# SERDES_10G0 register map
Vendor: Texas Instruments
Registers are 32-bit, read-write, reset 0x0 unless marked. A register's access mark holds for its fields unless they carry their own. Offsets are as the file gives them; [hi:lo] are bit positions; {n}, {i} and the like mark numbered series.

## SERDES_10G0 (part 4 of 5)
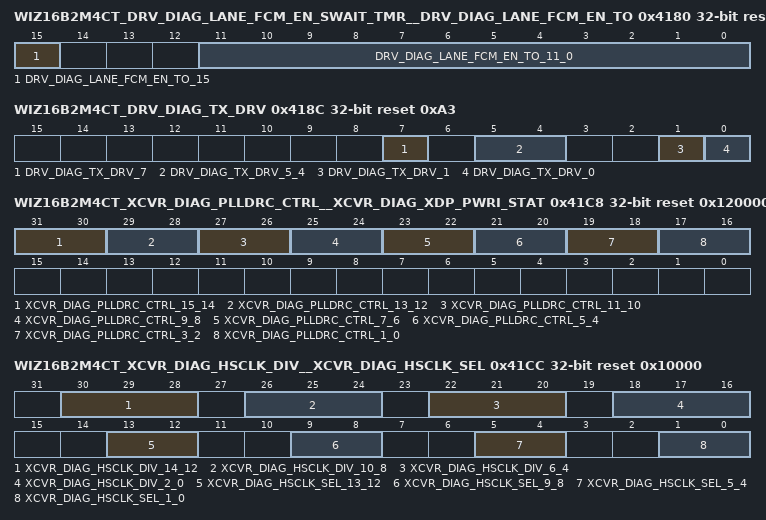
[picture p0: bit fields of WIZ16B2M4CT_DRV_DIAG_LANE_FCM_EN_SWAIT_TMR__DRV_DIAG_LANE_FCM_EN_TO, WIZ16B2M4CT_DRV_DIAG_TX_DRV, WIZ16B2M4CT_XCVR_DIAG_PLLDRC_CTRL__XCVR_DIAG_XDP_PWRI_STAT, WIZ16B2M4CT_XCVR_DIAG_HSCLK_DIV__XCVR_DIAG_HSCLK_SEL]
0x4180 WIZ16B2M4CT_DRV_DIAG_LANE_FCM_EN_SWAIT_TMR__DRV_DIAG_LANE_FCM_EN_TO reset 0x1F4 — Lane fast common mode enable timeout register
  [15] DRV_DIAG_LANE_FCM_EN_TO_15 — Bypass fast establishment of common mode enable: When enabled, the fast establishment of common mode function will be bypassed. When bypassed, the lane fast common mode enable timeout value field in this register can be used to implement a programmable delay between when fast establishment of common mode is normally initiated, and when it will complete.
  [11:0] DRV_DIAG_LANE_FCM_EN_TO_11_0 — Lane fast common mode enable timeout value: The usage of the value of this field is a function of the state of the bypass fast establishment of common mode enable bit in this register. Bypass disabled (normal operation): This specifies the maximum number of reference clock cycles the fast establishment of common mode process will wait for the tx_{p,m} signals to be reported as above the reference voltage, before timing out. The default value of this register corresponds to a delay of 20 uSec. Bypass enabled: This can be used to specify the number of reference clock cycles between when fast establishment of common mode would normally be initiated, and when it is acknowledged to have been completed.
0x4184 WIZ16B2M4CT_DRV_DIAG_LANE_FCM_EN_TUNE__DRV_DIAG_LANE_FCM_EN_MGN_TMR reset 0x96 — Lane fast common mode enable margin timer register
  [11:0] DRV_DIAG_LANE_FCM_EN_MGN_TMR_11_0 — Lane fast common mode enable margin timer value: This specifies the number of reference clock cycles the fast establishment of common mode process will enable all the margin segments for. The default value of this register corresponds to a delay of 6 uSec.
0x418C WIZ16B2M4CT_DRV_DIAG_TX_DRV reset 0xA3 — TX driver diagnostic register
  [7] DRV_DIAG_TX_DRV_7 — TX boost enable: Increases the transmitter amplitude for fast data transitions, by controlling the txda_drv_boost_en signal going to the analog.
  [5:4] DRV_DIAG_TX_DRV_5_4 — TX boost tune: Controls the transmitter boost amplitude when the transmitter boost function is enabled using the TX boost enable bit in this register, by controlling the txda_drv_boost_tune signal going to the analog. The following specifies the encoding of this field. 2'b00: Minimum Boost 2'b01: 2'b10: 2'b11: Maximum Boost
  [1] DRV_DIAG_TX_DRV_1 — TX pre-driver pull up control: When the pre-driver is disabled, this bit controls the state of the pre-driver output, by controlling the txda_drv_predrv_pullup signal going to the analog. 1'b0 : Pulled low 1'b1 : Pulled high
  [0] DRV_DIAG_TX_DRV_0 — TX driver margin type: Selects the margining type the driver will operate in, by controlling the txda_drv_margin_type signal going to the analog. 1'b0 : Classical margining - High power margining that complies with the driver differential and common-mode output impedance specs. 1'b1 : Low-Power margining - Low power margining that complies with the driver differential output impedance spec. However, this violates the driver common-mode output impedance spec to save power whenever a reduced swing driver configuration is used. Note that when fast establishment of common mode is active, the analog signal that this drives will be forced to 1'b0.
0x41C8 WIZ16B2M4CT_XCVR_DIAG_PLLDRC_CTRL__XCVR_DIAG_XDP_PWRI_STAT reset 0x120000 — Transceiver transceiver data path power island control status register
  [31:30] XCVR_DIAG_PLLDRC_CTRL_15_14 — Digital PLL clock select standard mode 3: This bit controls which full rate PLL clock is selected, when xcvr_standard_mode is set to 2'b11. 2'b00 : PLL clock 0 from the PLL 0. 2'b01 : PLL clock 1 from the PLL 0. 2'b10 : PLL clock 0 from the PLL 1. 2'b11 : PLL clock 1 from the PLL 1.
  [29:28] XCVR_DIAG_PLLDRC_CTRL_13_12 — Digital PLL data rate divider standard mode 3 value: This field will directly control the xcvr_pll_clk_datart_div signal, which controls which divided clock is selected when generating the xcvr_pll_clk_datart clock, when xcvr_standard_mode is set to 2'b11. 2'b00 : Divide by 1. 2'b01 : Divide by 2. 2'b10 : Divide by 4. 2'b11 : Divide by 8.
  [27:26] XCVR_DIAG_PLLDRC_CTRL_11_10 — Digital PLL clock select standard mode 2: This bit controls which full rate PLL clock is selected, when xcvr_standard_mode is set to 2'b10. 2'b00 : PLL clock 0 from the PLL 0. 2'b01 : PLL clock 1 from the PLL 0. 2'b10 : PLL clock 0 from the PLL 1. 2'b11 : PLL clock 1 from the PLL 1.
  [25:24] XCVR_DIAG_PLLDRC_CTRL_9_8 — Digital PLL data rate divider standard mode 2 value: This field will directly control the xcvr_pll_clk_datart_div signal, which controls which divided clock is selected when generating the xcvr_pll_clk_datart clock, when xcvr_standard_mode is set to 2'b10. 2'b00 : Divide by 1. 2'b01 : Divide by 2. 2'b10 : Divide by 4. 2'b11 : Divide by 8.
  [23:22] XCVR_DIAG_PLLDRC_CTRL_7_6 — Digital PLL clock select standard mode 1: This bit controls which full rate PLL clock is selected, when xcvr_standard_mode is set to 2'b01. 2'b00 : PLL clock 0 from the PLL 0. 2'b01 : PLL clock 1 from the PLL 0. 2'b10 : PLL clock 0 from the PLL 1. 2'b11 : PLL clock 1 from the PLL 1.
  [21:20] XCVR_DIAG_PLLDRC_CTRL_5_4 — Digital PLL data rate divider standard mode 1 value: This field will directly control the xcvr_pll_clk_datart_div signal, which controls which divided clock is selected when generating the xcvr_pll_clk_datart clock, when xcvr_standard_mode is set to 2'b01. 2'b00 : Divide by 1. 2'b01 : Divide by 2. 2'b10 : Divide by 4. 2'b11 : Divide by 8.
  [19:18] XCVR_DIAG_PLLDRC_CTRL_3_2 — Digital PLL clock select standard mode 0: This bit controls which full rate PLL clock is selected, when xcvr_standard_mode is set to 2'b00. 2'b00 : PLL clock 0 from the PLL 0. 2'b01 : PLL clock 1 from the PLL 0. 2'b10 : PLL clock 0 from the PLL 1. 2'b11 : PLL clock 1 from the PLL 1.
  [17:16] XCVR_DIAG_PLLDRC_CTRL_1_0 — Digital PLL data rate divider standard mode 0 value: This field will directly control the xcvr_pll_clk_datart_div signal, which controls which divided clock is selected when generating the xcvr_pll_clk_datart clock, when xcvr_standard_mode is set to 2'b00. 2'b00 : Divide by 1. 2'b01 : Divide by 2. 2'b10 : Divide by 4. 2'b11 : Divide by 8.
0x41CC WIZ16B2M4CT_XCVR_DIAG_HSCLK_DIV__XCVR_DIAG_HSCLK_SEL reset 0x10000 — Transceiver high speed clock select register
  [30:28] XCVR_DIAG_HSCLK_DIV_14_12 — Transceiver clock divider select standard mode 3: This field selects the divider value used to divide the selected analog high speed clock by when generating the transmit and receive clocks, when xcvr_standard_mode is set to 2'b11, by driving the xcvrda_xcvr_clk_div_sel signal to the analog, as specified below. 3'b000: Div 1 3'b001: Div 2 3'b010: Div 3 3'b011: Div 4 3'b100: Div 5 3'b101: Div 6 3'b110: Div 7 3'b111: Div 8
  [26:24] XCVR_DIAG_HSCLK_DIV_10_8 — Transceiver clock divider select standard mode 2: This field selects the divider value used to divide the selected analog high speed clock by when generating the transmit and receive clocks, when xcvr_standard_mode is set to 2'b10, by driving the xcvrda_xcvr_clk_div_sel signal to the analog, as specified below. 3'b000: Div 1 3'b001: Div 2 3'b010: Div 3 3'b011: Div 4 3'b100: Div 5 3'b101: Div 6 3'b110: Div 7 3'b111: Div 8
  [22:20] XCVR_DIAG_HSCLK_DIV_6_4 — Transceiver clock divider select standard mode 1: This field selects the divider value used to divide the selected analog high speed clock by when generating the transmit and receive clocks, when xcvr_standard_mode is set to 2'b01, by driving the xcvrda_xcvr_clk_div_sel signal to the analog, as specified below. 3'b000: Div 1 3'b001: Div 2 3'b010: Div 3 3'b011: Div 4 3'b100: Div 5 3'b101: Div 6 3'b110: Div 7 3'b111: Div 8
  [18:16] XCVR_DIAG_HSCLK_DIV_2_0 — Transceiver clock divider select standard mode 0: This field selects the divider value used to divide the selected analog high speed clock by when generating the transmit and receive clocks, when xcvr_standard_mode is set to 2'b00, by driving the xcvrda_xcvr_clk_div_sel signal to the analog, as specified below. 3'b000: Div 1 3'b001: Div 2 3'b010: Div 3 3'b011: Div 4 3'b100: Div 5 3'b101: Div 6 3'b110: Div 7 3'b111: Div 8
  [13:12] XCVR_DIAG_HSCLK_SEL_13_12 — High speed clock select standard mode 3: This specifies which analog high speed clock is selected when xcvr_standard_mode is set to 2'b11, by driving the xcvrda_clk_sel signal to the analog, as specified below. 2'b00 : clock 0. 2'b01 : clock 1. 2'b10 : Reserved. 2'b11 : Reserved.
  [9:8] XCVR_DIAG_HSCLK_SEL_9_8 — High speed clock select standard mode 2: This specifies which analog high speed clock is selected when xcvr_standard_mode is set to 2'b10, by driving the xcvrda_clk_sel signal to the analog, as specified below. 2'b00 : clock 0. 2'b01 : clock 1. 2'b10 : Reserved. 2'b11 : Reserved.
  [5:4] XCVR_DIAG_HSCLK_SEL_5_4 — High speed clock select standard mode 1: This specifies which analog high speed clock is selected when xcvr_standard_mode is set to 2'b01, by driving the xcvrda_clk_sel signal to the analog, as specified below. 2'b00 : clock 0. 2'b01 : clock 1. 2'b10 : Reserved. 2'b11 : Reserved.
  [1:0] XCVR_DIAG_HSCLK_SEL_1_0 — High speed clock select standard mode 0: This specifies which analog high speed clock is selected when xcvr_standard_mode is set to 2'b00, by driving the xcvrda_clk_sel signal to the analog, as specified below. 2'b00 : clock 0. 2'b01 : clock 1. 2'b10 : Reserved. 2'b11 : Reserved.
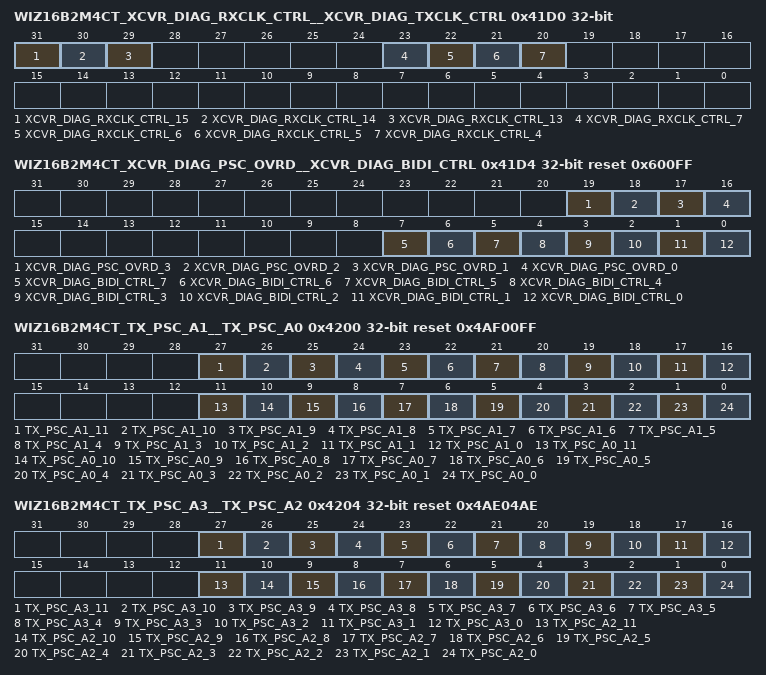
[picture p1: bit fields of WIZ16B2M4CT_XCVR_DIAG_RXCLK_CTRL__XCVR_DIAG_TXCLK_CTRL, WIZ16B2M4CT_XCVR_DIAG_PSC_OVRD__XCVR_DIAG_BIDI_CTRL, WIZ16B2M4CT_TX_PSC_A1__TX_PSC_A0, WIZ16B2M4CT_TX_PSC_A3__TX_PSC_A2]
0x41D0 WIZ16B2M4CT_XCVR_DIAG_RXCLK_CTRL__XCVR_DIAG_TXCLK_CTRL — TX clock control register
  [31] XCVR_DIAG_RXCLK_CTRL_15 — RX deserializer clock invert: This bit is used to optionally invert the deserializer clock (rxda_des_clk) for diagnostic purposes.
  [30] XCVR_DIAG_RXCLK_CTRL_14 — RX 2x clock enable: This bit enables the receiver 2x clock function, by driving the rxda_des_clk_2x_en signal going to the analog. Note that this clock is only designed to be used in modes where the data width is 20 bits. 1'b0 : Disabled 1'b1 : Enabled
  [29] XCVR_DIAG_RXCLK_CTRL_13 — RX PI E path clock select: Controls which PI clock drives the E path clocks, by driving the rxda_pi_i_drv_e_en signal going to the analog. 1'b0: E PI clock 1'b1: IQ PI clock
  [23] XCVR_DIAG_RXCLK_CTRL_7 — PI output clock divider enable standard mode 3: This bit controls the rxda_pi_out_clk_div_en to enable the PI output clock divider, when xcvr_standard_mode is set to 2'b11. 1'b0 : Disabled 1'b1 : Enabled
  [22] XCVR_DIAG_RXCLK_CTRL_6 — PI output clock divider enable standard mode 2: This bit controls the rxda_pi_out_clk_div_en to enable the PI output clock divider, when xcvr_standard_mode is set to 2'b10. 1'b0 : Disabled 1'b1 : Enabled
  [21] XCVR_DIAG_RXCLK_CTRL_5 — PI output clock divider enable standard mode 1: This bit controls the rxda_pi_out_clk_div_en to enable the PI output clock divider, when xcvr_standard_mode is set to 2'b01. 1'b0 : Disabled 1'b1 : Enabled
  [20] XCVR_DIAG_RXCLK_CTRL_4 — PI output clock divider enable standard mode 0: This bit controls the rxda_pi_out_clk_div_en to enable the PI output clock divider, when xcvr_standard_mode is set to 2'b00. 1'b0 : Disabled 1'b1 : Enabled
0x41D4 WIZ16B2M4CT_XCVR_DIAG_PSC_OVRD__XCVR_DIAG_BIDI_CTRL reset 0x600FF — Transceiver bidirectional control register
  [19] XCVR_DIAG_PSC_OVRD_3 — Receiver DFE enable mask value standard mode 3: This bit will controls the rx_dfe_eq_enable_std_mask digital signal, which can be used to mask off the rxda_dfe_eq_enable signal coming from the power state controller and going into the analog, when xcvr_standard_mode is set to 2'b11. 1'b0 : The signal will be masked off. 1'b1 : The signal to pass through unchanged.
  [18] XCVR_DIAG_PSC_OVRD_2 — Receiver DFE enable mask value standard mode 2: This bit will controls the rx_dfe_eq_enable_std_mask digital signal, which can be used to mask off the rxda_dfe_eq_enable signal coming from the power state controller and going into the analog, when xcvr_standard_mode is set to 2'b10. 1'b0 : The signal will be masked off. 1'b1 : The signal to pass through unchanged.
  [17] XCVR_DIAG_PSC_OVRD_1 — Receiver DFE enable mask value standard mode 1: This bit will controls the rx_dfe_eq_enable_std_mask digital signal, which can be used to mask off the rxda_dfe_eq_enable signal coming from the power state controller and going into the analog, when xcvr_standard_mode is set to 2'b01. 1'b0 : The signal will be masked off. 1'b1 : The signal to pass through unchanged.
  [16] XCVR_DIAG_PSC_OVRD_0 — Receiver DFE enable mask value standard mode 0: This bit will controls the rx_dfe_eq_enable_std_mask digital signal, which can be used to mask off the rxda_dfe_eq_enable signal coming from the power state controller and going into the analog, when xcvr_standard_mode is set to 2'b00. 1'b0 : The signal will be masked off. 1'b1 : The signal to pass through unchanged.
  [7] XCVR_DIAG_BIDI_CTRL_7 — Receiver enable standard mode 3: When bidirectional bumps are implemented in the transceiver, this bit is a global enable for the receiver function, when xcvr_standard_mode is set to 2'b11. When bidirectional bumps are not implemented, this bit will be reset to 1'b1, and should not be changed. When bidirectional bumps are implemented in the transceiver, this bit and the corresponding transmitter enable bit must not be set to 1'b1 at the same time. 1'b0 : RX disabled 1'b1 : RX enabled
  [6] XCVR_DIAG_BIDI_CTRL_6 — Receiver enable standard mode 2: When bidirectional bumps are implemented in the transceiver, this bit is a global enable for the receiver function, when xcvr_standard_mode is set to 2'b10. When bidirectional bumps are not implemented, this bit will be reset to 1'b1, and should not be changed. When bidirectional bumps are implemented in the transceiver, this bit and the corresponding transmitter enable bit must not be set to 1'b1 at the same time. 1'b0 : RX disabled 1'b1 : RX enabled
  [5] XCVR_DIAG_BIDI_CTRL_5 — Receiver enable standard mode 1: When bidirectional bumps are implemented in the transceiver, this bit is a global enable for the receiver function, when xcvr_standard_mode is set to 2'b01. When bidirectional bumps are not implemented, this bit will be reset to 1'b1, and should not be changed. When bidirectional bumps are implemented in the transceiver, this bit and the corresponding transmitter enable bit must not be set to 1'b1 at the same time. 1'b0 : RX disabled 1'b1 : RX enabled
  [4] XCVR_DIAG_BIDI_CTRL_4 — Receiver enable standard mode 0: When bidirectional bumps are implemented in the transceiver, this bit is a global enable for the receiver function, when xcvr_standard_mode is set to 2'b00. When bidirectional bumps are not implemented, this bit will be reset to 1'b1, and should not be changed. When bidirectional bumps are implemented in the transceiver, this bit and the corresponding transmitter enable bit must not be set to 1'b1 at the same time. 1'b0 : RX disabled 1'b1 : RX enabled
  [3] XCVR_DIAG_BIDI_CTRL_3 — Transmitter enable standard mode 3: When bidirectional bumps are implemented in the transceiver, this bit is a global enable for the transmitter function, when xcvr_standard_mode is set to 2'b11. When bidirectional bumps are not implemented, this bit will be reset to 1'b1, and should not be changed. When bidirectional bumps are implemented in the transceiver, this bit and the corresponding receiver enable bit must not be set to 1'b1 at the same time. 1'b0 : TX disabled 1'b1 : TX enabled
  [2] XCVR_DIAG_BIDI_CTRL_2 — Transmitter enable standard mode 2: When bidirectional bumps are implemented in the transceiver, this bit is a global enable for the transmitter function, when xcvr_standard_mode is set to 2'b10. When bidirectional bumps are not implemented, this bit will be reset to 1'b1, and should not be changed. When bidirectional bumps are implemented in the transceiver, this bit and the corresponding receiver enable bit must not be set to 1'b1 at the same time. 1'b0 : TX disabled 1'b1 : TX enabled
  [1] XCVR_DIAG_BIDI_CTRL_1 — Transmitter enable standard mode 1: When bidirectional bumps are implemented in the transceiver, this bit is a global enable for the transmitter function, when xcvr_standard_mode is set to 2'b01. When bidirectional bumps are not implemented, this bit will be reset to 1'b1, and should not be changed. When bidirectional bumps are implemented in the transceiver, this bit and the corresponding receiver enable bit must not be set to 1'b1 at the same time. 1'b0 : TX disabled 1'b1 : TX enabled
  [0] XCVR_DIAG_BIDI_CTRL_0 — Transmitter enable standard mode 0: When bidirectional bumps are implemented in the transceiver, this bit is a global enable for the transmitter function, when xcvr_standard_mode is set to 2'b00. When bidirectional bumps are not implemented, this bit will be reset to 1'b1, and should not be changed. When bidirectional bumps are implemented in the transceiver, this bit and the corresponding receiver enable bit must not be set to 1'b1 at the same time. 1'b0 : TX disabled 1'b1 : TX enabled
0x4200 WIZ16B2M4CT_TX_PSC_A1__TX_PSC_A0 reset 0x4AF00FF — Transmitter A0 power state definition register
  [27] TX_PSC_A1_11 — TX driver common mode enable extend control
  [26] TX_PSC_A1_10 — Force txda_lfps_sel active
  [25] TX_PSC_A1_9 — LFPS clock gate enable
  [24] TX_PSC_A1_8 — Reserved - spare
  [23] TX_PSC_A1_7 — Transmitter low current mode
  [22] TX_PSC_A1_6 — Transmitter mission mode enable
  [21] TX_PSC_A1_5 — TX driver common mode enable
  [20] TX_PSC_A1_4 — TX driver enable
  [19] TX_PSC_A1_3 — TX post-emphasis enable (C+1)
  [18] TX_PSC_A1_2 — TX pre-emphasis enable (C-1)
  [17] TX_PSC_A1_1 — TX pre-driver enable
  [16] TX_PSC_A1_0 — TX serializer enable
  [11] TX_PSC_A0_11 — TX driver common mode enable extend control: Specifies which power states the tx_cmn_mode_en_ext signal is considered valid in and can be used to force the driver to continue to be in the common mode state.
  [10] TX_PSC_A0_10 — Force txda_lfps_sel active: Setting this bit forces the txda_lfps_sel signal going to the analog to be driven active. Note that this function is implemented for additional power savings. In the analog, this signal controls a MUX select associated with the driver. Setting this bit to 1'b1 will force the MUX to select the LFPS data path. By selecting this path in low power states, instead of the serializer path, the driver inputs will be driven to 1'b0, instead of having the potential to toggle.
  [9] TX_PSC_A0_9 — LFPS clock gate enable: Enables the LFPS clock gate when an LFPS clock is required.
  [8] TX_PSC_A0_8 — Reserved - spare
  [7] TX_PSC_A0_7 — Transmitter low current mode: Enables a low current consumption mode within the common mode voltage circuit in the driver, via the txda_drv_idle_lowi_en signal going to the analog.
  [6] TX_PSC_A0_6 — Transmitter mission mode enable: Enables the analog circuits in the driver required to run in mission mode, via the txda_drv_mission_en signal going to the analog.
  [5] TX_PSC_A0_5 — TX driver common mode enable: Enables the common mode voltage circuits in the driver.
  [4] TX_PSC_A0_4 — TX driver enable: Enables the transmitter driver, via the H bridge driver controller.
  [3] TX_PSC_A0_3 — TX post-emphasis enable (C+1): Enables the transmitter circuits related to the post-emphasis function.
  [2] TX_PSC_A0_2 — TX pre-emphasis enable (C-1): Enables the transmitter circuits related to the pre-emphasis function.
  [1] TX_PSC_A0_1 — TX pre-driver enable: Enables the transmitter pre-driver, driver data selection MUX, and receiver detect.
  [0] TX_PSC_A0_0 — TX serializer enable: Enables the serializer and related clock divider circuits.
0x4204 WIZ16B2M4CT_TX_PSC_A3__TX_PSC_A2 reset 0x4AE04AE — Transmitter A2 power state definition register
  [27] TX_PSC_A3_11 — TX driver common mode enable extend control
  [26] TX_PSC_A3_10 — Force txda_lfps_sel active
  [25] TX_PSC_A3_9 — LFPS clock gate enable
  [24] TX_PSC_A3_8 — Reserved - spare
  [23] TX_PSC_A3_7 — Transmitter low current mode
  [22] TX_PSC_A3_6 — Transmitter mission mode enable
  [21] TX_PSC_A3_5 — TX driver common mode enable
  [20] TX_PSC_A3_4 — TX driver enable
  [19] TX_PSC_A3_3 — TX post-emphasis enable (C+1)
  [18] TX_PSC_A3_2 — TX pre-emphasis enable (C-1)
  [17] TX_PSC_A3_1 — TX pre-driver enable
  [16] TX_PSC_A3_0 — TX serializer enable
  [11] TX_PSC_A2_11 — TX driver common mode enable extend control
  [10] TX_PSC_A2_10 — Force txda_lfps_sel active
  [9] TX_PSC_A2_9 — LFPS clock gate enable
  [8] TX_PSC_A2_8 — Reserved - spare
  [7] TX_PSC_A2_7 — Transmitter low current mode
  [6] TX_PSC_A2_6 — Transmitter mission mode enable
  [5] TX_PSC_A2_5 — TX driver common mode enable
  [4] TX_PSC_A2_4 — TX driver enable
  [3] TX_PSC_A2_3 — TX post-emphasis enable (C+1)
  [2] TX_PSC_A2_2 — TX pre-emphasis enable (C-1)
  [1] TX_PSC_A2_1 — TX pre-driver enable
  [0] TX_PSC_A2_0 — TX serializer enable
0x4244 WIZ16B2M4CT_TX_RCVDET_ST_TMR__TX_RCVDET_EN_TMR reset 0x9C40000 — Transmit receiver detect enable timer register
  [31:16] TX_RCVDET_ST_TMR_15_0 — Start wait time value: This is the number of clocks the receiver detect state machine waits between driving the txda_rcvdet_start signal active and checking the results on the txda_rcvdet_detected_n signal coming from the analog. The default required wait time is 100us.
0x6000 WIZ16B2M4CT_RESERVEDBIT13ADDRESSB — Reserved Address bit 13 area B
  [31:0] RES_BIT13_ADR_B — Write only test region B
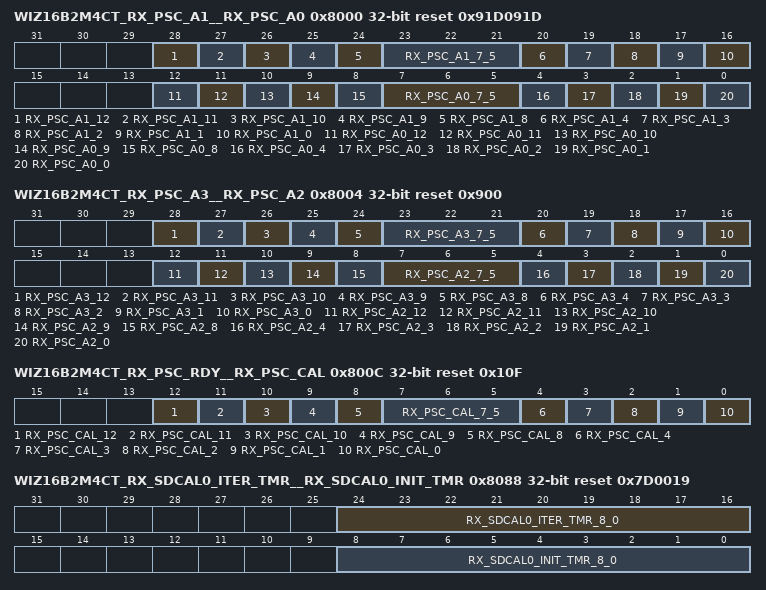
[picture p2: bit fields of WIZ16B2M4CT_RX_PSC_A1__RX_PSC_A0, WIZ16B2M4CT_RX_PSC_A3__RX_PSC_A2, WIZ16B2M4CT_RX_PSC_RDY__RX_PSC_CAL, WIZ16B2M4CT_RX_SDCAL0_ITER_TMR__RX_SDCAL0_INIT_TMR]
0x8000 WIZ16B2M4CT_RX_PSC_A1__RX_PSC_A0 reset 0x91D091D — Receiver A0 power state definition register
  [28] RX_PSC_A1_12 — RX signal detect enable extend control
  [27] RX_PSC_A1_11 — RX signal detect filter enable
  [26] RX_PSC_A1_10 — RX LFPS detect filter enable
  [25] RX_PSC_A1_9 — Reserved - spare
  [24] RX_PSC_A1_8 — RX signal detect enable
  [23:21] RX_PSC_A1_7_5 — Reserved - spare
  [20] RX_PSC_A1_4 — RX equalizer engine enable
  [19] RX_PSC_A1_3 — RX DFE equalization enable.
  [18] RX_PSC_A1_2 — RX PI enable
  [17] RX_PSC_A1_1 — RX e path enable (calibration and eye surf only)
  [16] RX_PSC_A1_0 — RX enable
  [12] RX_PSC_A0_12 — RX signal detect enable extend control: Specifies which power states the rx_sig_det_en_ext signal is considered valid in and can be used to force the signal detect functions to remain on.
  [11] RX_PSC_A0_11 — RX signal detect filter enable: Enables the receiver signal detect filter function in the digital receiver controller.
  [10] RX_PSC_A0_10 — RX LFPS detect filter enable: Enables the receiver LFPS detect filter function in the digital receiver controller.
  [9] RX_PSC_A0_9 — Reserved - spare
  [8] RX_PSC_A0_8 — RX signal detect enable: Enables the receiver signal detect function. This drives the rxda_sd_en signal going to the analog. Note that this bit needs to be active for LFPS detect functions to work, because these functions share the same analog circuits.
  [7:5] RX_PSC_A0_7_5 — Reserved - spare
  [4] RX_PSC_A0_4 — RX equalizer engine enable: Specifies which power state the REE runs in. 1'b0: Disabled 1'b1: Enabled
  [3] RX_PSC_A0_3 — RX DFE equalization enable: Enables the receiver DFE equalization circuits, via the rxda_dfe_eq_enable signal.
  [2] RX_PSC_A0_2 — RX PI enable: Enables the receiver circuits related to the PI and associated clocking components.
  [1] RX_PSC_A0_1 — RX e path enable (calibration and eye surf only) : Enables the receiver circuits related to the eye plot PI and e path deserializer for calibration and eye surf.
  [0] RX_PSC_A0_0 — RX enable: Enables the receiver circuits related to the CDRLF, Sampler, FE, and Deserializer.
0x8004 WIZ16B2M4CT_RX_PSC_A3__RX_PSC_A2 reset 0x900 — Receiver A2 power state definition register
  [28] RX_PSC_A3_12 — RX signal detect enable extend control
  [27] RX_PSC_A3_11 — RX signal detect filter enable
  [26] RX_PSC_A3_10 — RX LFPS detect filter enable
  [25] RX_PSC_A3_9 — Reserved - spare
  [24] RX_PSC_A3_8 — RX signal detect enable
  [23:21] RX_PSC_A3_7_5 — Reserved - spare
  [20] RX_PSC_A3_4 — RX equalizer engine enable
  [19] RX_PSC_A3_3 — RX DFE equalization enable.
  [18] RX_PSC_A3_2 — RX PI enable
  [17] RX_PSC_A3_1 — RX e path enable (calibration and eye surf only)
  [16] RX_PSC_A3_0 — RX enable
  [12] RX_PSC_A2_12 — RX signal detect enable extend control
  [11] RX_PSC_A2_11 — RX signal detect filter enable
  [10] RX_PSC_A2_10 — RX LFPS detect filter enable
  [9] RX_PSC_A2_9 — Reserved - spare
  [8] RX_PSC_A2_8 — RX signal detect enable
  [7:5] RX_PSC_A2_7_5 — Reserved - spare
  [4] RX_PSC_A2_4 — RX equalizer engine enable
  [3] RX_PSC_A2_3 — RX DFE equalization enable.
  [2] RX_PSC_A2_2 — RX PI enable
  [1] RX_PSC_A2_1 — RX e path enable (calibration and eye surf only)
  [0] RX_PSC_A2_0 — RX enable
0x800C WIZ16B2M4CT_RX_PSC_RDY__RX_PSC_CAL reset 0x10F — Receiver calibration power state definition register
  [12] RX_PSC_CAL_12 — RX signal detect enable extend control
  [11] RX_PSC_CAL_11 — RX signal detect filter enable
  [10] RX_PSC_CAL_10 — RX LFPS detect filter enable
  [9] RX_PSC_CAL_9 — Reserved - spare
  [8] RX_PSC_CAL_8 — RX signal detect enable
  [7:5] RX_PSC_CAL_7_5 — Reserved - spare
  [4] RX_PSC_CAL_4 — RX equalizer engine enable
  [3] RX_PSC_CAL_3 — RX DFE equalization enable.
  [2] RX_PSC_CAL_2 — RX PI enable
  [1] RX_PSC_CAL_1 — RX e path enable (calibration and eye surf only)
  [0] RX_PSC_CAL_0 — RX enable
0x8088 WIZ16B2M4CT_RX_SDCAL0_ITER_TMR__RX_SDCAL0_INIT_TMR reset 0x7D0019 — Signal detect calibration 0 initialization timer register
  [24:16] RX_SDCAL0_ITER_TMR_8_0 — Iteration wait timer value: This is the number of cmn_ref_clk clocks to wait between when a value is placed on the calibration code signals going to the analog, and when the comparator value coming from the analog circuits can be checked. Note that this results in the minimum number of cmn_ref_clk clocks required to wait 5 uSec. Note that this should never be set to a value of less than 3.
  [8:0] RX_SDCAL0_INIT_TMR_8_0 — Initialization wait timer value: This is the number of cmn_ref_clk clocks to wait between when the analog calibration circuits are enabled, and when the first values are placed on the calibration code signals going to the analog. Note that this results in the minimum number of cmn_ref_clk clocks required to wait 1 uSec. Note that this should never be set to a value of less than 1.
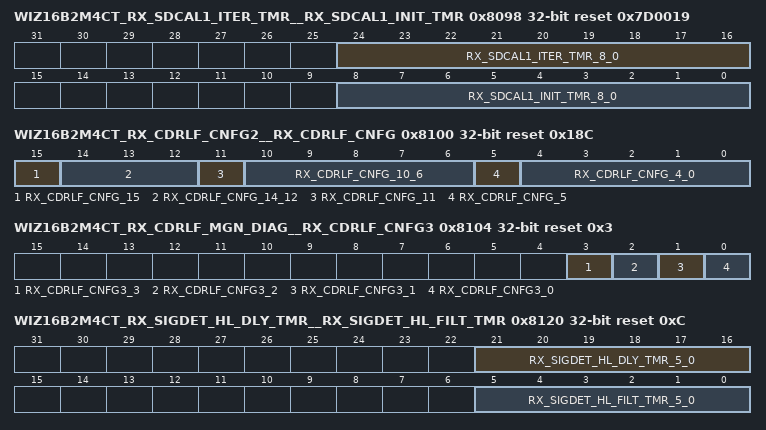
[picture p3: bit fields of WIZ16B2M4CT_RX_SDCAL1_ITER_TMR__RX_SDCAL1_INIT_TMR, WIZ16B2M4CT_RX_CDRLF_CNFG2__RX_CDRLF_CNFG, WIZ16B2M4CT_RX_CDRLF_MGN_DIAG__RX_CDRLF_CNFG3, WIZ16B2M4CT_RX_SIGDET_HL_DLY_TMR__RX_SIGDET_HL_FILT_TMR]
0x8098 WIZ16B2M4CT_RX_SDCAL1_ITER_TMR__RX_SDCAL1_INIT_TMR reset 0x7D0019 — Signal detect calibration 1 initialization timer register
  [24:16] RX_SDCAL1_ITER_TMR_8_0 — Iteration wait timer value: This is the number of cmn_ref_clk clocks to wait between when a value is placed on the calibration code signals going to the analog, and when the comparator value coming from the analog circuits can be checked. Note that this results in the minimum number of cmn_ref_clk clocks required to wait 5 uSec. Note that this should never be set to a value of less than 3.
  [8:0] RX_SDCAL1_INIT_TMR_8_0 — Initialization wait timer value: This is the number of cmn_ref_clk clocks to wait between when the analog calibration circuits are enabled, and when the first values are placed on the calibration code signals going to the analog. Note that this results in the minimum number of cmn_ref_clk clocks required to wait 1 uSec. Note that this should never be set to a value of less than 1.
0x8100 WIZ16B2M4CT_RX_CDRLF_CNFG2__RX_CDRLF_CNFG reset 0x18C — CDRLF configuration register (!)
  [15] RX_CDRLF_CNFG_15 — CDLRF reset hold: When active (1'b1), the CDRLF will be held in reset beyond the time that it would normally be released by its asynchronous release signals. The CDRLF will be held in reset until this bit is deactivated (1'b0). Note: This signal is intended be for verification purposes only. It should be set to 1'b0 for normal operation.
  [14:12] RX_CDRLF_CNFG_14_12 — CDRLF diagnostic mode control: This field controls the information driven on the rx_pi_val_ln_{15:0}[7:0] signal, when in diagnostics mode.
  [11] RX_CDRLF_CNFG_11 — CDRLF second order loop disable: Activating (1'b1) this bit will disable the CDRLF second order loop. Note: This signal is intended be for verification purposes only. It should be set to 1'b0 for normal operation.
  [10:6] RX_CDRLF_CNFG_10_6 — CDRLF second order loop sigma delta update rate: This is the value that is added to or subtracted from the second order loop accumulator register when the serial data sample clock is detected as being out of phase with the serial data on a given parallel data word cycle. This is part of the CDRLF averaging function.
  [5] RX_CDRLF_CNFG_5 — CDRLF first order loop disable: Activating (1'b1) this bit will disable the CDRLF first order loop. Note: This signal is intended to be for verification purposes only. It should be set to 1'b0 for normal operation.
  [4:0] RX_CDRLF_CNFG_4_0 — CDRLF first order loop sigma delta update rate: This is the value that is added to or subtracted from the first order loop accumulator register when the serial data sample clock is detected as being out of phase with the serial data on a given parallel data word cycle. This is part of the CDRLF averaging function.
0x8104 WIZ16B2M4CT_RX_CDRLF_MGN_DIAG__RX_CDRLF_CNFG3 reset 0x3 — CDRLF configuration register 3 (!)
  [3] RX_CDRLF_CNFG3_3 — CDRLF data filter enable standard mode 3 : Enables the filter function for the data that feeds into the CDRLF from the deserializer, using the rxda_cdrlf_data_filter_en_n signal, when xcvr_standard_mode is set to 2'b11. 1'b0 : Enable filter of 1010 patterns from the CDRLF. 1'b1 : No CDRLF data filter function enabled.
  [2] RX_CDRLF_CNFG3_2 — CDRLF data filter enable standard mode 2 : Enables the filter function for the data that feeds into the CDRLF from the deserializer, using the rxda_cdrlf_data_filter_en_n signal, when xcvr_standard_mode is set to 2'b10. 1'b0 : Enable filter of 1010 patterns from the CDRLF. 1'b1 : No CDRLF data filter function enabled.
  [1] RX_CDRLF_CNFG3_1 — CDRLF data filter enable standard mode 1 : Enables the filter function for the data that feeds into the CDRLF from the deserializer, using the rxda_cdrlf_data_filter_en_n signal, when xcvr_standard_mode is set to 2'b01. 1'b0 : Enable filter of 1010 patterns from the CDRLF. 1'b1 : No CDRLF data filter function enabled.
  [0] RX_CDRLF_CNFG3_0 — CDRLF data filter enable standard mode 0 : Enables the filter function for the data that feeds into the CDRLF from the deserializer, using the rxda_cdrlf_data_filter_en_n signal, when xcvr_standard_mode is set to 2'b00. 1'b0 : Enable filter of 1010 patterns from the CDRLF. 1'b1 : No CDRLF data filter function enabled.
0x8120 WIZ16B2M4CT_RX_SIGDET_HL_DLY_TMR__RX_SIGDET_HL_FILT_TMR reset 0xC — Receiver signal detect filter high to low filter timer register (!)
  [21:16] RX_SIGDET_HL_DLY_TMR_5_0 — Signal detect filter high to low delay timer value: This is the value loaded into the delay timer in the signal detect high to low filter circuit.
  [5:0] RX_SIGDET_HL_FILT_TMR_5_0 — Signal detect filter high to low filter timer value: This is the value loaded into the filter timer in the signal detect high to low filter circuit.
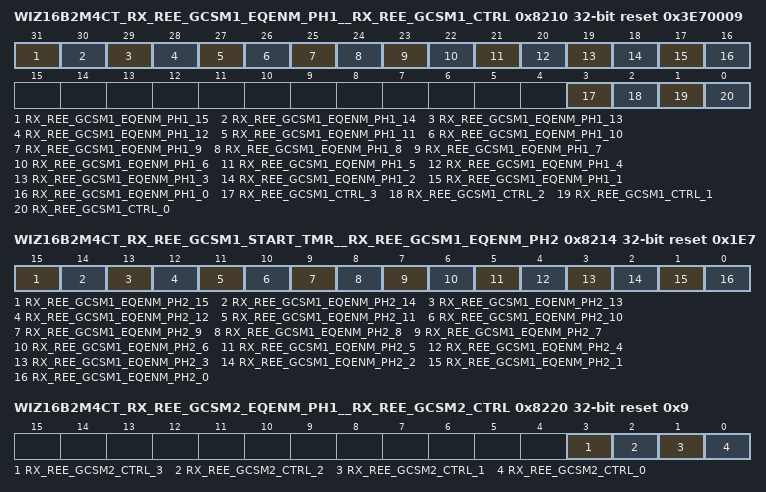
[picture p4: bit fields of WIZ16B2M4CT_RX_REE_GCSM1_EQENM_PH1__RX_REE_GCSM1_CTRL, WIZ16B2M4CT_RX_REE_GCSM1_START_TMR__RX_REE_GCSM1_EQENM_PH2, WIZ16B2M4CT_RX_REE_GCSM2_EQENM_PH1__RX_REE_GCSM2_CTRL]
0x8210 WIZ16B2M4CT_RX_REE_GCSM1_EQENM_PH1__RX_REE_GCSM1_CTRL reset 0x3E70009 — REE general control state machine 1 control register
  [31] RX_REE_GCSM1_EQENM_PH1_15 — Reserved - spare
  [30] RX_REE_GCSM1_EQENM_PH1_14 — Ignore 1010 controller : When set to 1'b1, this function is enabled when the general control state machine 1 is controlling the REE.
  [29] RX_REE_GCSM1_EQENM_PH1_13 — TX equalization evaluator : When set to 1'b1, this function is enabled when the general control state machine 1 is controlling the REE.
  [28] RX_REE_GCSM1_EQENM_PH1_12 — TX post cursor control : When set to 1'b1, this function is enabled when the general control state machine 1 is controlling the REE.
  [27] RX_REE_GCSM1_EQENM_PH1_11 — TX pre cursor control : When set to 1'b1, this function is enabled when the general control state machine 1 is controlling the REE.
  [26] RX_REE_GCSM1_EQENM_PH1_10 — Short channel correction : When set to 1'b1, this function is enabled when the general control state machine 1 is controlling the REE.
  [25] RX_REE_GCSM1_EQENM_PH1_9 — RX attenuation : When set to 1'b1, this function is enabled when the general control state machine 1 is controlling the REE.
  [24] RX_REE_GCSM1_EQENM_PH1_8 — RX VGA gain : When set to 1'b1, this function is enabled when the general control state machine 1 is controlling the REE.
  [23] RX_REE_GCSM1_EQENM_PH1_7 — RX offset correction coefficient : When set to 1'b1, this function is enabled when the general control state machine 1 is controlling the REE.
  [22] RX_REE_GCSM1_EQENM_PH1_6 — RX peaking amp gain : When set to 1'b1, this function is enabled when the general control state machine 1 is controlling the REE.
  [21] RX_REE_GCSM1_EQENM_PH1_5 — RX low frequency equalizer adaptive control : When set to 1'b1, this function is enabled when the general control state machine 1 is controlling the REE.
  [20] RX_REE_GCSM1_EQENM_PH1_4 — Reserved - spare
  [19] RX_REE_GCSM1_EQENM_PH1_3 — Reserved - spare
  [18] RX_REE_GCSM1_EQENM_PH1_2 — RX tap 3 : When set to 1'b1, this function is enabled when the general control state machine 1 is controlling the REE.
  [17] RX_REE_GCSM1_EQENM_PH1_1 — RX tap 2 : When set to 1'b1, this function is enabled when the general control state machine 1 is controlling the REE.
  [16] RX_REE_GCSM1_EQENM_PH1_0 — RX tap 1 : When set to 1'b1, this function is enabled when the general control state machine 1 is controlling the REE.
  [3] RX_REE_GCSM1_CTRL_3 — Equalization function reset enable: Enables the reset of the functions controlled by this state machine, using the rx_ree_fcn_reset_n signal, when the equalization mode changes. 1'b1 : Enabled 1'b0 : Disabled
  [2] RX_REE_GCSM1_CTRL_2 — Loop enable: Controls when the equalization functions in this state machine are run one time or loop continuously.
  [1] RX_REE_GCSM1_CTRL_1 — Force run equalization: Setting this bit to a 1'b1, will force the general control state machine to run, independent of the macro functions that normally run the equalization.
  [0] RX_REE_GCSM1_CTRL_0 — Enable: This bit enables the general control state machine function. 1'b1 : Enabled 1'b0 : Disabled
0x8214 WIZ16B2M4CT_RX_REE_GCSM1_START_TMR__RX_REE_GCSM1_EQENM_PH2 reset 0x1E7 — REE general control state machine 1 phase 2 equalization enable mask register
  [15] RX_REE_GCSM1_EQENM_PH2_15 — Reserved - spare
  [14] RX_REE_GCSM1_EQENM_PH2_14 — Ignore 1010 controller : When set to 1'b1, this function is enabled when the general control state machine 1 is controlling the REE.
  [13] RX_REE_GCSM1_EQENM_PH2_13 — TX equalization evaluator : When set to 1'b1, this function is enabled when the general control state machine 1 is controlling the REE.
  [12] RX_REE_GCSM1_EQENM_PH2_12 — TX post cursor control : When set to 1'b1, this function is enabled when the general control state machine 1 is controlling the REE.
  [11] RX_REE_GCSM1_EQENM_PH2_11 — TX pre cursor control : When set to 1'b1, this function is enabled when the general control state machine 1 is controlling the REE.
  [10] RX_REE_GCSM1_EQENM_PH2_10 — Short channel correction : When set to 1'b1, this function is enabled when the general control state machine 1 is controlling the REE.
  [9] RX_REE_GCSM1_EQENM_PH2_9 — RX attenuation : When set to 1'b1, this function is enabled when the general control state machine 1 is controlling the REE.
  [8] RX_REE_GCSM1_EQENM_PH2_8 — RX VGA gain : When set to 1'b1, this function is enabled when the general control state machine 1 is controlling the REE.
  [7] RX_REE_GCSM1_EQENM_PH2_7 — RX offset correction coefficient : When set to 1'b1, this function is enabled when the general control state machine 1 is controlling the REE.
  [6] RX_REE_GCSM1_EQENM_PH2_6 — RX peaking amp gain : When set to 1'b1, this function is enabled when the general control state machine 1 is controlling the REE.
  [5] RX_REE_GCSM1_EQENM_PH2_5 — RX low frequency equalizer adaptive control : When set to 1'b1, this function is enabled when the general control state machine 1 is controlling the REE.
  [4] RX_REE_GCSM1_EQENM_PH2_4 — Reserved - spare
  [3] RX_REE_GCSM1_EQENM_PH2_3 — Reserved - spare
  [2] RX_REE_GCSM1_EQENM_PH2_2 — RX tap 3 : When set to 1'b1, this function is enabled when the general control state machine 1 is controlling the REE.
  [1] RX_REE_GCSM1_EQENM_PH2_1 — RX tap 2 : When set to 1'b1, this function is enabled when the general control state machine 1 is controlling the REE.
  [0] RX_REE_GCSM1_EQENM_PH2_0 — RX tap 1 : When set to 1'b1, this function is enabled when the general control state machine 1 is controlling the REE.
0x8220 WIZ16B2M4CT_RX_REE_GCSM2_EQENM_PH1__RX_REE_GCSM2_CTRL reset 0x9 — REE general control state machine 2 control register
  [3] RX_REE_GCSM2_CTRL_3 — Equalization function reset enable: Enables the reset of the functions controlled by this state machine, using the rx_ree_fcn_reset_n signal, when the equalization mode changes. 1'b1 : Enabled 1'b0 : Disabled
  [2] RX_REE_GCSM2_CTRL_2 — Loop enable: Controls when the equalization functions in this state machine are run one time or loop continuously.
  [1] RX_REE_GCSM2_CTRL_1 — Force run equalization: Setting this bit to a 1'b1, will force the general control state machine to run, independent of the macro functions that normally run the equalization.
  [0] RX_REE_GCSM2_CTRL_0 — Enable: This bit enables the general control state machine function. 1'b1 : Enabled 1'b0 : Disabled
